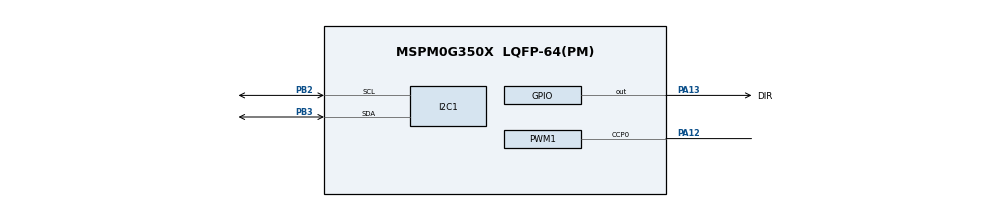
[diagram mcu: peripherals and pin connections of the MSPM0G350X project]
/**
 * @cliArgs --device "MSPM0G350X" --part "Default" --package "LQFP-64(PM)" --product "mspm0_sdk@2.09.00.02"
 * @versions {"tool":"1.26.0+4407"}
 */

/**
 * Import the modules used in this configuration.
 */
const Board         = scripting.addModule("/ti/driverlib/Board");
const GPIO          = scripting.addModule("/ti/driverlib/GPIO", {}, false);
const GPIO1         = GPIO.addInstance();
const GPIO2         = GPIO.addInstance();
const GPIO3         = GPIO.addInstance();
const I2C           = scripting.addModule("/ti/driverlib/I2C", {}, false);
const I2C1          = I2C.addInstance();
const PWM           = scripting.addModule("/ti/driverlib/PWM", {}, false);
const PWM1          = PWM.addInstance();
const TIMER         = scripting.addModule("/ti/driverlib/TIMER", {}, false);
const TIMER1        = TIMER.addInstance();
const ProjectConfig = scripting.addModule("/ti/project_config/ProjectConfig");

/**
 * Write custom configuration values to the imported modules.
 */

GPIO1.$name                         = "GPIO_GRP_0";
GPIO1.associatedPins[0].$name       = "DIR";
GPIO1.associatedPins[0].pin.$assign = "PA13";

GPIO2.$name                   = "GPIO_GRP_1";
GPIO2.associatedPins[0].$name = "PIN_1";

GPIO3.$name                              = "LIMITS";
GPIO3.port                               = "PORTA";
GPIO3.associatedPins.create(2);
GPIO3.associatedPins[0].$name            = "LEFT";
GPIO3.associatedPins[0].direction        = "INPUT";
GPIO3.associatedPins[0].internalResistor = "PULL_UP";
GPIO3.associatedPins[0].assignedPin      = "9";
GPIO3.associatedPins[1].$name            = "RIGHT";
GPIO3.associatedPins[1].direction        = "INPUT";
GPIO3.associatedPins[1].internalResistor = "PULL_UP";
GPIO3.associatedPins[1].assignedPin      = "10";

I2C1.$name                     = "I2C_0";
I2C1.basicEnableController     = true;
I2C1.peripheral.sdaPin.$assign = "PB3";
I2C1.peripheral.sclPin.$assign = "PB2";
I2C1.sdaPinConfig.$name        = "ti_driverlib_gpio_GPIOPinGeneric0";
I2C1.sclPinConfig.$name        = "ti_driverlib_gpio_GPIOPinGeneric1";

PWM1.$name                      = "PWM_0";
PWM1.timerCount                 = 3200;
PWM1.peripheral.ccp0Pin.$assign = "PA12";
PWM1.PWM_CHANNEL_0.$name        = "ti_driverlib_pwm_PWMTimerCC0";
PWM1.PWM_CHANNEL_1.$name        = "ti_driverlib_pwm_PWMTimerCC1";
PWM1.ccp0PinConfig.$name        = "ti_driverlib_gpio_GPIOPinGeneric2";
PWM1.ccp1PinConfig.$name        = "ti_driverlib_gpio_GPIOPinGeneric3";

const SYSCTL = scripting.addModule("/ti/driverlib/SYSCTL", {}, false);

TIMER1.$name       = "TIMER_0";
TIMER1.timerMode   = "PERIODIC";
TIMER1.timerPeriod = "5 ms";
TIMER1.timerClkDiv = 8;
TIMER1.interrupts  = ["ZERO"];

/**
 * Pinmux solution for unlocked pins/peripherals. This ensures that minor changes to the automatic solver in a future
 * version of the tool will not impact the pinmux you originally saw.  These lines can be completely deleted in order to
 * re-solve from scratch.
 */
Board.peripheral.$suggestSolution            = "DEBUGSS";
Board.peripheral.swclkPin.$suggestSolution   = "PA20";
Board.peripheral.swdioPin.$suggestSolution   = "PA19";
GPIO2.associatedPins[0].pin.$suggestSolution = "PB13";
GPIO3.associatedPins[0].pin.$suggestSolution = "PA9";
GPIO3.associatedPins[1].pin.$suggestSolution = "PA10";
I2C1.peripheral.$suggestSolution             = "I2C1";
PWM1.peripheral.$suggestSolution             = "TIMG0";
PWM1.peripheral.ccp1Pin.$suggestSolution     = "PA24";
SYSCTL.peripheral.$suggestSolution           = "SYSCTL";
TIMER1.peripheral.$suggestSolution           = "TIMA0";
